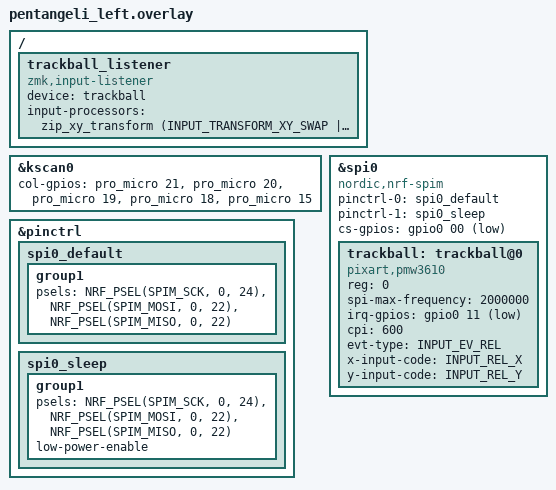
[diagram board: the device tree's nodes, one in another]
#include "pentangeli.dtsi"

&kscan0 {
    col-gpios
        = <&pro_micro 21 GPIO_ACTIVE_HIGH>
        , <&pro_micro 20 GPIO_ACTIVE_HIGH>
        , <&pro_micro 19 GPIO_ACTIVE_HIGH>
        , <&pro_micro 18 GPIO_ACTIVE_HIGH>
        , <&pro_micro 15 GPIO_ACTIVE_HIGH>
        ;
};


// Trackball
// https://github.com/badjeff/zmk-pmw3610-driver
&pinctrl {
    spi0_default: spi0_default {
        group1 {
            psels = <NRF_PSEL(SPIM_SCK, 0, 24)>,
                <NRF_PSEL(SPIM_MOSI, 0, 22)>,
                <NRF_PSEL(SPIM_MISO, 0, 22)>;
        };
    };

    spi0_sleep: spi0_sleep {
        group1 {
            psels = <NRF_PSEL(SPIM_SCK, 0, 24)>,
                <NRF_PSEL(SPIM_MOSI, 0, 22)>,
                <NRF_PSEL(SPIM_MISO, 0, 22)>;
            low-power-enable;
        };
    };
};

#include <zephyr/dt-bindings/input/input-event-codes.h>

&spi0 {
    status = "okay";
    compatible = "nordic,nrf-spim";
    pinctrl-0 = <&spi0_default>;
    pinctrl-1 = <&spi0_sleep>;
    pinctrl-names = "default", "sleep";
    cs-gpios = <&gpio0 00 GPIO_ACTIVE_LOW>;

    trackball: trackball@0 {
        status = "okay";
        compatible = "pixart,pmw3610";
        reg = <0>;
        spi-max-frequency = <2000000>;
        irq-gpios = <&gpio0 11 (GPIO_ACTIVE_LOW | GPIO_PULL_UP)>;
        cpi = <600>;
        evt-type = <INPUT_EV_REL>;
        x-input-code = <INPUT_REL_X>;
        y-input-code = <INPUT_REL_Y>;
    };
};

#include <dt-bindings/zmk/input_transform.h>

/ {
  trackball_listener {
    compatible = "zmk,input-listener";
    device = <&trackball>;
    input-processors = <&zip_xy_transform (INPUT_TRANSFORM_XY_SWAP | INPUT_TRANSFORM_X_INVERT | INPUT_TRANSFORM_Y_INVERT)>;
  };
};
